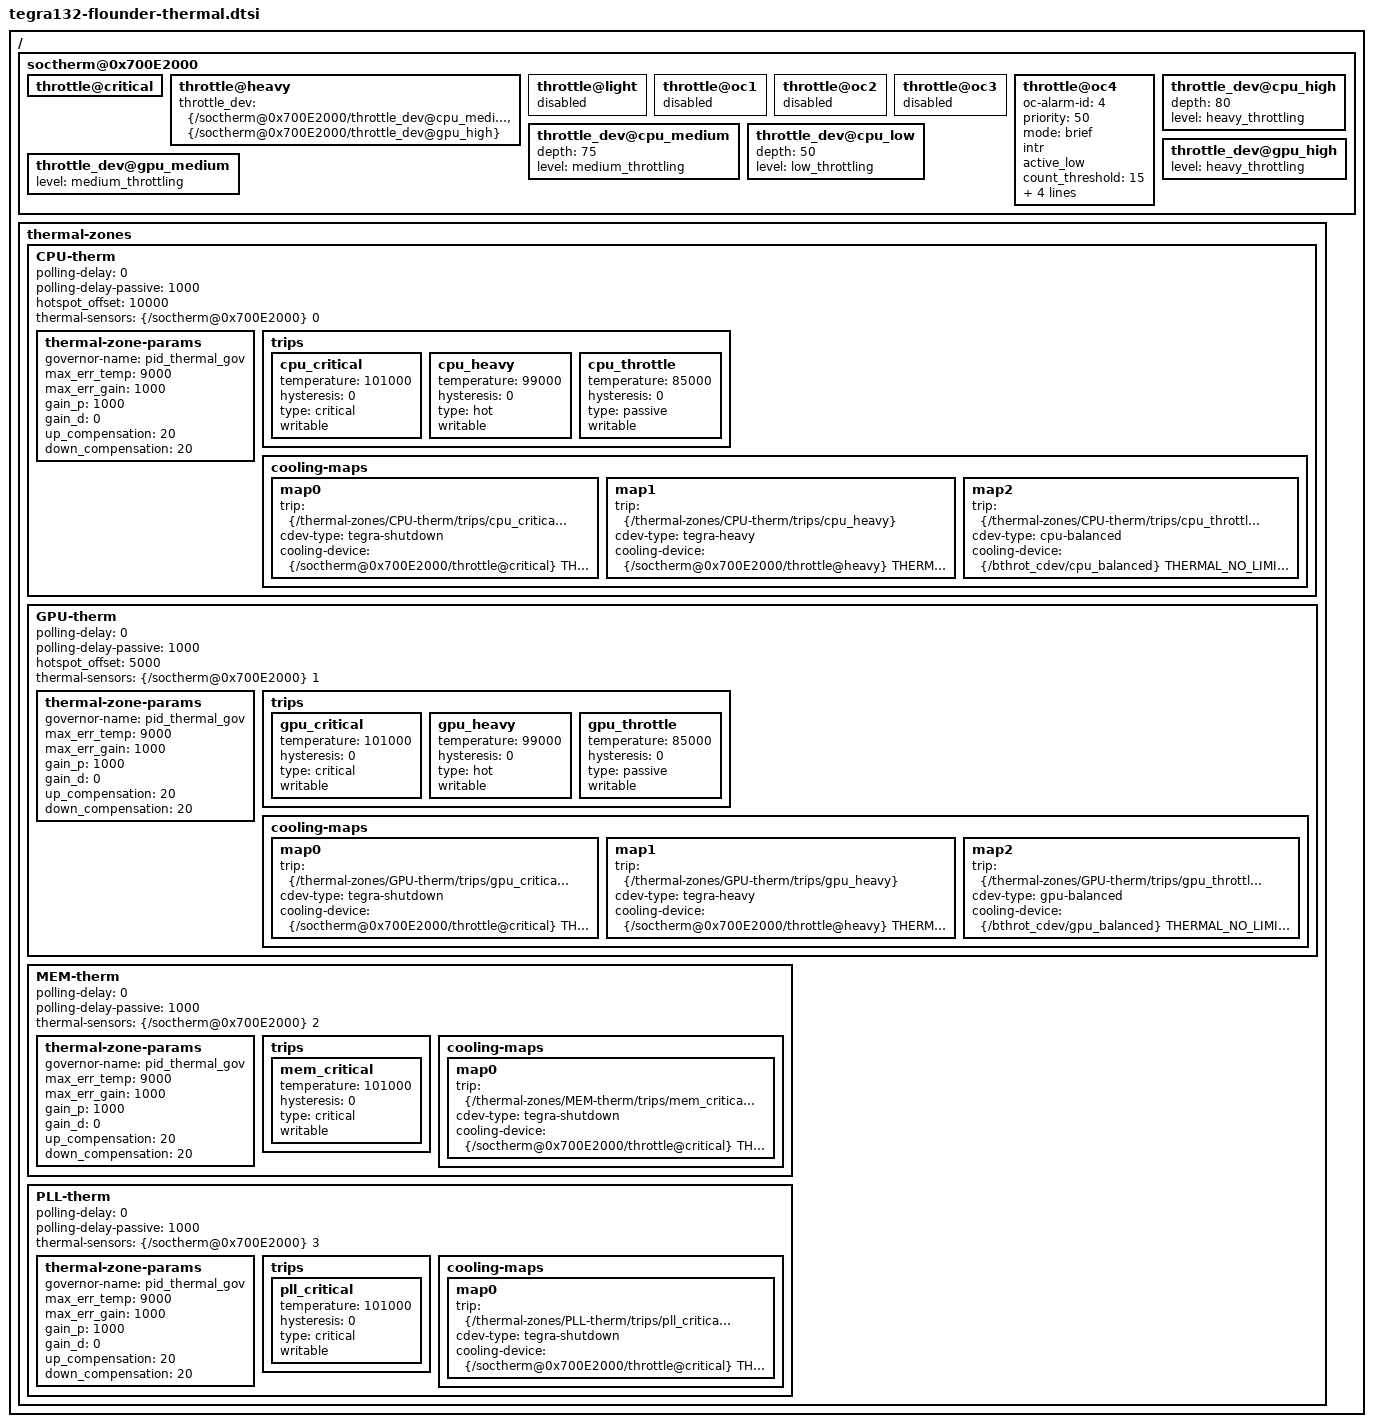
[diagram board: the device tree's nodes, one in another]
#include <dt-bindings/thermal/thermal.h>

/ {
	soctherm@0x700E2000 {
		status = "okay";
		throttle@critical {
			status = "okay";
		};
		throttle@heavy {
			status = "okay";
			throttle_dev = <&{/soctherm@0x700E2000/throttle_dev@cpu_medium}
					&{/soctherm@0x700E2000/throttle_dev@gpu_high}>;
		};
		throttle@light {
			status = "disabled";
		};
		throttle@oc1 {
			status = "disabled";
		};
		throttle@oc2 {
			status = "disabled";
		};
		throttle@oc3 {
			status = "disabled";
		};
		throttle@oc4 {
			status = "okay";
			device_type = "throttlectl";
			oc-alarm-id = <4>;
			priority = <50>;
			mode = "brief";
			intr;
			active_low;
			count_threshold = <15>;
			filter = <5100000>;
			throttle_dev = <&{/soctherm@0x700E2000/throttle_dev@cpu_low}
					&{/soctherm@0x700E2000/throttle_dev@gpu_low}>;
		};
		throttle_dev@cpu_high {
			status = "okay";
			depth = <80>;
			level = "heavy_throttling";
		};
		throttle_dev@cpu_medium {
			status = "okay";
			depth = <75>;
			level = "medium_throttling";
		};
		throttle_dev@cpu_low {
			status = "okay";
			depth = <50>;
			level = "low_throttling";
		};
		throttle_dev@gpu_high {
			status = "okay";
			level = "heavy_throttling";
		};
		throttle_dev@gpu_medium {
			status = "okay";
			level = "medium_throttling";

		};
	};

	thermal-zones {

		CPU-therm {
			status 			= "okay";
			polling-delay		= <0>;
			polling-delay-passive	= <1000>;
			hotspot_offset		= <10000>;
			thermal-sensors		= <&{/soctherm@0x700E2000} 0>;
			thermal-zone-params {
				governor-name = "pid_thermal_gov";
				max_err_temp = <9000>;
				max_err_gain = <1000>;
				gain_p = <1000>;
				gain_d = <0>;
				up_compensation = <20>;
				down_compensation = <20>;
			};
			trips {
				cpu_critical {
					temperature = <101000>;
					hysteresis = <0>;
					type = "critical";
					writable;
				};
				cpu_heavy {
					temperature = <99000>;
					hysteresis = <0>;
					type = "hot";
					writable;
				};
				cpu_throttle {
					temperature = <85000>;
					hysteresis = <0>;
					type = "passive";
					writable;
				};
			};
			cooling-maps {
				map0 {
					trip = <&{/thermal-zones/CPU-therm/trips/cpu_critical}>;
					cdev-type = "tegra-shutdown";
					cooling-device = <&{/soctherm@0x700E2000/throttle@critical}
						THERMAL_NO_LIMIT THERMAL_NO_LIMIT>;
				};
				map1 {
					trip = <&{/thermal-zones/CPU-therm/trips/cpu_heavy}>;
					cdev-type = "tegra-heavy";
					cooling-device = <&{/soctherm@0x700E2000/throttle@heavy}
						THERMAL_NO_LIMIT THERMAL_NO_LIMIT>;
				};
				map2 {
					trip = <&{/thermal-zones/CPU-therm/trips/cpu_throttle}>;
					cdev-type = "cpu-balanced";
					cooling-device = <&{/bthrot_cdev/cpu_balanced}
						THERMAL_NO_LIMIT THERMAL_NO_LIMIT>;
				};
			};
		};

		GPU-therm {
			status		 	= "okay";
			polling-delay		= <0>;
			polling-delay-passive	= <1000>;
			hotspot_offset		= <5000>;
			thermal-sensors		= <&{/soctherm@0x700E2000} 1>;
			thermal-zone-params {
				governor-name = "pid_thermal_gov";
				max_err_temp = <9000>;
				max_err_gain = <1000>;
				gain_p = <1000>;
				gain_d = <0>;
				up_compensation = <20>;
				down_compensation = <20>;
			};
			trips {
				gpu_critical {
					temperature = <101000>;
					hysteresis = <0>;
					type = "critical";
					writable;
				};
				gpu_heavy {
					temperature = <99000>;
					hysteresis = <0>;
					type = "hot";
					writable;
				};
				gpu_throttle {
					temperature = <85000>;
					hysteresis = <0>;
					type = "passive";
					writable;
				};
			};
			cooling-maps {
				map0 {
					trip = <&{/thermal-zones/GPU-therm/trips/gpu_critical}>;
					cdev-type = "tegra-shutdown";
					cooling-device = <&{/soctherm@0x700E2000/throttle@critical}
						THERMAL_NO_LIMIT THERMAL_NO_LIMIT>;
				};
				map1 {
					trip = <&{/thermal-zones/GPU-therm/trips/gpu_heavy}>;
					cdev-type = "tegra-heavy";
					cooling-device = <&{/soctherm@0x700E2000/throttle@heavy}
						THERMAL_NO_LIMIT THERMAL_NO_LIMIT>;
				};
				map2 {
					trip = <&{/thermal-zones/GPU-therm/trips/gpu_throttle}>;
					cdev-type = "gpu-balanced";
					cooling-device = <&{/bthrot_cdev/gpu_balanced}
						THERMAL_NO_LIMIT THERMAL_NO_LIMIT>;
				};
			};
		};
		
		MEM-therm {
			status 			= "okay";
			polling-delay		= <0>;
			polling-delay-passive	= <1000>;
			thermal-sensors		= <&{/soctherm@0x700E2000} 2>;
			thermal-zone-params {
				governor-name = "pid_thermal_gov";
				max_err_temp = <9000>;
				max_err_gain = <1000>;
				gain_p = <1000>;
				gain_d = <0>;
				up_compensation = <20>;
				down_compensation = <20>;
			};

			trips {
				mem_critical {
					temperature = <101000>;
					hysteresis = <0>;
					type = "critical";
					writable;
				};
			};
			cooling-maps {
				map0 {
					trip = <&{/thermal-zones/MEM-therm/trips/mem_critical}>;
					cdev-type = "tegra-shutdown";
					cooling-device = <&{/soctherm@0x700E2000/throttle@critical}
						THERMAL_NO_LIMIT THERMAL_NO_LIMIT>;
				};
			};
		};

		PLL-therm {
			status 			= "okay";
			polling-delay		= <0>;
			polling-delay-passive	= <1000>;
			thermal-sensors		= <&{/soctherm@0x700E2000} 3>;
			thermal-zone-params {
				governor-name = "pid_thermal_gov";
				max_err_temp = <9000>;
				max_err_gain = <1000>;
				gain_p = <1000>;
				gain_d = <0>;
				up_compensation = <20>;
				down_compensation = <20>;
			};

			trips {
				pll_critical {
					temperature = <101000>;
					hysteresis = <0>;
					type = "critical";
					writable;
				};
			};
			cooling-maps {
				map0 {
					trip = <&{/thermal-zones/PLL-therm/trips/pll_critical}>;
					cdev-type = "tegra-shutdown";
					cooling-device = <&{/soctherm@0x700E2000/throttle@critical}
						THERMAL_NO_LIMIT THERMAL_NO_LIMIT>;
				};
			};
		};
	};
};
